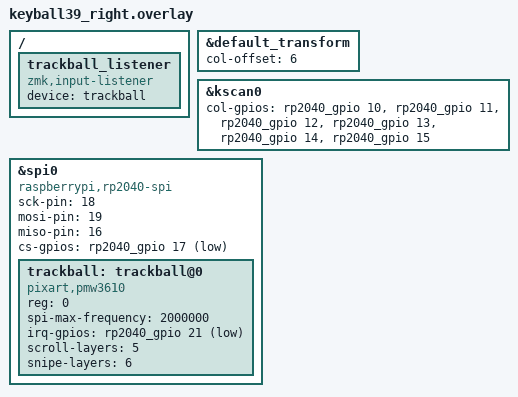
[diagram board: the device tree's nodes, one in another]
/*
 * Copyright (c) 2020 ZMK Contributors
 *
 * SPDX-License-Identifier: MIT
 */

#include "keyball39.dtsi"

&default_transform {
    col-offset = <6>;
};

&kscan0 {
    col-gpios
        = <&rp2040_gpio 10 GPIO_ACTIVE_HIGH>
        , <&rp2040_gpio 11 GPIO_ACTIVE_HIGH>
        , <&rp2040_gpio 12 GPIO_ACTIVE_HIGH>
        , <&rp2040_gpio 13 GPIO_ACTIVE_HIGH>
        , <&rp2040_gpio 14 GPIO_ACTIVE_HIGH>
        , <&rp2040_gpio 15 GPIO_ACTIVE_HIGH>
        ;
};

&spi0 {
    status = "okay";
    compatible = "raspberrypi,rp2040-spi";
    sck-pin = <18>;    // SPI Clock (SCK)
    mosi-pin = <19>;   // SPI MOSI
    miso-pin = <16>;   // SPI MISO
    cs-gpios = <&rp2040_gpio 17 GPIO_ACTIVE_LOW>; // Chip Select (CS) for PMW3610

    trackball: trackball@0 {
        status = "okay";
        compatible = "pixart,pmw3610";
        reg = <0>;
        spi-max-frequency = <2000000>;
        irq-gpios = <&rp2040_gpio 21 (GPIO_ACTIVE_LOW | GPIO_PULL_UP)>;
        scroll-layers = <5>;
        snipe-layers = <6>;
    };
};

/ {
    trackball_listener {
        compatible = "zmk,input-listener";
        device = <&trackball>;
    };
};
